# CY8C5868AXI_LP035 register map
File version: 0.1
CY8C58LP
Registers are 8-bit, read-write, no defined reset value unless marked. A register's access mark holds for its fields unless they carry their own. Offsets are from the block's base; lines under a group give offsets from that group; [hi:lo] are bit positions; {n}, {i} and the like mark numbered series; 'fields as' and 'values as' point back to an identical list; <NAME> marks a mode.

## Memory map
0x00000000 Timer_Line_End
0x00000000 Counter_Far_Row
0x00000000 Counter_Near_Row
0x00000000 Timer_Line_Begin
0x00000000 Timer_Comp_Ignore_2
0x00000000 Timer_Comp_Ignore_1
0x00000000 Timer_Wheel_Tick
0x00000000 Counter_Tick_Timeout
0x00000000 PWM_Motor
0x00000000 PWM_Servo
0x00000000 Counter_PID

## Timer_Line_End
Base 0x00000000
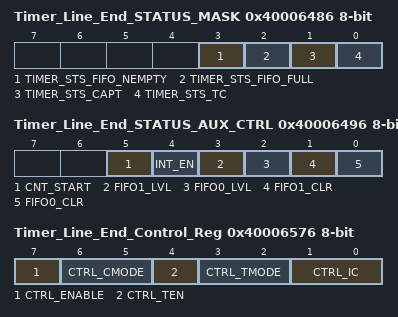
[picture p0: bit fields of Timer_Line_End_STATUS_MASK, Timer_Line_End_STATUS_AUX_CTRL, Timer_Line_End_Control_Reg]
0x40006486 Timer_Line_End_STATUS_MASK — UDB Status bits Interrupt Mask Enable Register
  [3] TIMER_STS_FIFO_NEMPTY ro — FIFO Empty status
  [2] TIMER_STS_FIFO_FULL ro — FIFO Full Status
  [1] TIMER_STS_CAPT ro — Enables the Interrupt on Capture
  [0] TIMER_STS_TC ro — Enables the Interrupt on TC
0x40006496 Timer_Line_End_STATUS_AUX_CTRL — UDB Auxilliary Control Register
  [5] CNT_START — FIFO0 clear
    0=E_CNT_START0 (Disable counter); 1=E_CNT_START1 (Enable counter)
  [4] INT_EN
    0=E_INT_EN0 (Interrupt disabled); 1=E_INT_EN1 (Interrupt enabled)
  [3] FIFO1_LVL — FIFO level
    0=E_FIFO_LVL_0 (FIFO LVL: input mode: FIFO not full; output mode: FIFO not empty); 1=E_FIFO_LVL_1 (FIFO LVL: input mode: FIFO at least 1/2 empty; output mode: FIFO at least 1/2 full)
  [2] FIFO0_LVL — FIFO level
    values as FIFO1_LVL
  [1] FIFO1_CLR — FIFO1 clear
    0=E_FIFO_CLR_0 (Normal FIFO operation); 1=E_FIFO_CLR_1 (Clear FIFO state)
  [0] FIFO0_CLR — FIFO0 clear
    values as FIFO1_CLR
0x40006504 Timer_Line_End_COUNTER 16-bit — UDB.A0 - Current Down Counter Value
0x40006524 Timer_Line_End_PERIOD 16-bit — UDB.D0 - Assigned Period
0x40006576 Timer_Line_End_Control_Reg — UDB Control Register - Assigned Control Register Value
  [7] CTRL_ENABLE — Enable the Timer
  [6:5] CTRL_CMODE — Capture Mode
  [4] CTRL_TEN — Trigger Enable Bit
  [3:2] CTRL_TMODE — Trigger Mode
  [1:0] CTRL_IC — Interrupt Count

## Counter_Far_Row
Base 0x00000000
0x40006404 Counter_Far_Row_COUNTER 16-bit — UDB.A0 - Current Counter Value
0x40006424 Counter_Far_Row_PERIOD 16-bit — UDB.D0 - Assigned Period
0x40006434 Counter_Far_Row_COMPARE 16-bit — UDB.D1 - Assigned Compare Value
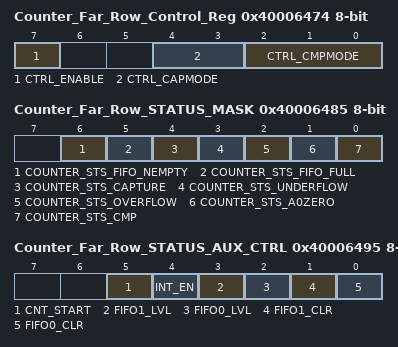
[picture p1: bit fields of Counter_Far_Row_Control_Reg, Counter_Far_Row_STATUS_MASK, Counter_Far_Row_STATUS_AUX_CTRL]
0x40006474 Counter_Far_Row_Control_Reg — UDB Control Register - Assigned Control Register Value
  [7] CTRL_ENABLE — Enable Counter
  [4:3] CTRL_CAPMODE — Capture mode
  [2:0] CTRL_CMPMODE — Compare mode
0x40006485 Counter_Far_Row_STATUS_MASK — UDB Status bits Interrupt Mask Enable Register
  [6] COUNTER_STS_FIFO_NEMPTY — FIFO Not Empty Status
  [5] COUNTER_STS_FIFO_FULL — FIFO Full Status
  [4] COUNTER_STS_CAPTURE — Capture Status
  [3] COUNTER_STS_UNDERFLOW — Underflow status
  [2] COUNTER_STS_OVERFLOW — Overflow status
  [1] COUNTER_STS_A0ZERO — A0 Zero ouput status
  [0] COUNTER_STS_CMP — Compare output status
0x40006495 Counter_Far_Row_STATUS_AUX_CTRL — UDB Auxilliary Control Register
  [5] CNT_START — FIFO0 clear
    0=E_CNT_START0 (Disable counter); 1=E_CNT_START1 (Enable counter)
  [4] INT_EN
    0=E_INT_EN0 (Interrupt disabled); 1=E_INT_EN1 (Interrupt enabled)
  [3] FIFO1_LVL — FIFO level
    0=E_FIFO_LVL_0 (FIFO LVL: input mode: FIFO not full; output mode: FIFO not empty); 1=E_FIFO_LVL_1 (FIFO LVL: input mode: FIFO at least 1/2 empty; output mode: FIFO at least 1/2 full)
  [2] FIFO0_LVL — FIFO level
    values as FIFO1_LVL
  [1] FIFO1_CLR — FIFO1 clear
    0=E_FIFO_CLR_0 (Normal FIFO operation); 1=E_FIFO_CLR_1 (Clear FIFO state)
  [0] FIFO0_CLR — FIFO0 clear
    values as FIFO1_CLR

## Counter_Near_Row
Base 0x00000000
0x40006402 Counter_Near_Row_COUNTER 16-bit — UDB.A0 - Current Counter Value
0x40006422 Counter_Near_Row_PERIOD 16-bit — UDB.D0 - Assigned Period
0x40006432 Counter_Near_Row_COMPARE 16-bit — UDB.D1 - Assigned Compare Value
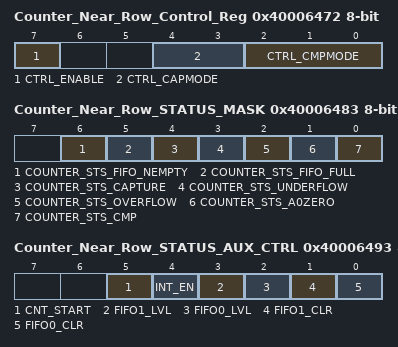
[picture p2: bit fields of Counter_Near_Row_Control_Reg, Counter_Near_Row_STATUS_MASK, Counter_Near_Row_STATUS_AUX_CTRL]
0x40006472 Counter_Near_Row_Control_Reg — UDB Control Register - Assigned Control Register Value
  [7] CTRL_ENABLE — Enable Counter
  [4:3] CTRL_CAPMODE — Capture mode
  [2:0] CTRL_CMPMODE — Compare mode
0x40006483 Counter_Near_Row_STATUS_MASK — UDB Status bits Interrupt Mask Enable Register
  [6] COUNTER_STS_FIFO_NEMPTY — FIFO Not Empty Status
  [5] COUNTER_STS_FIFO_FULL — FIFO Full Status
  [4] COUNTER_STS_CAPTURE — Capture Status
  [3] COUNTER_STS_UNDERFLOW — Underflow status
  [2] COUNTER_STS_OVERFLOW — Overflow status
  [1] COUNTER_STS_A0ZERO — A0 Zero ouput status
  [0] COUNTER_STS_CMP — Compare output status
0x40006493 Counter_Near_Row_STATUS_AUX_CTRL — UDB Auxilliary Control Register
  [5] CNT_START — FIFO0 clear
    0=E_CNT_START0 (Disable counter); 1=E_CNT_START1 (Enable counter)
  [4] INT_EN
    0=E_INT_EN0 (Interrupt disabled); 1=E_INT_EN1 (Interrupt enabled)
  [3] FIFO1_LVL — FIFO level
    0=E_FIFO_LVL_0 (FIFO LVL: input mode: FIFO not full; output mode: FIFO not empty); 1=E_FIFO_LVL_1 (FIFO LVL: input mode: FIFO at least 1/2 empty; output mode: FIFO at least 1/2 full)
  [2] FIFO0_LVL — FIFO level
    values as FIFO1_LVL
  [1] FIFO1_CLR — FIFO1 clear
    0=E_FIFO_CLR_0 (Normal FIFO operation); 1=E_FIFO_CLR_1 (Clear FIFO state)
  [0] FIFO0_CLR — FIFO0 clear
    values as FIFO1_CLR
